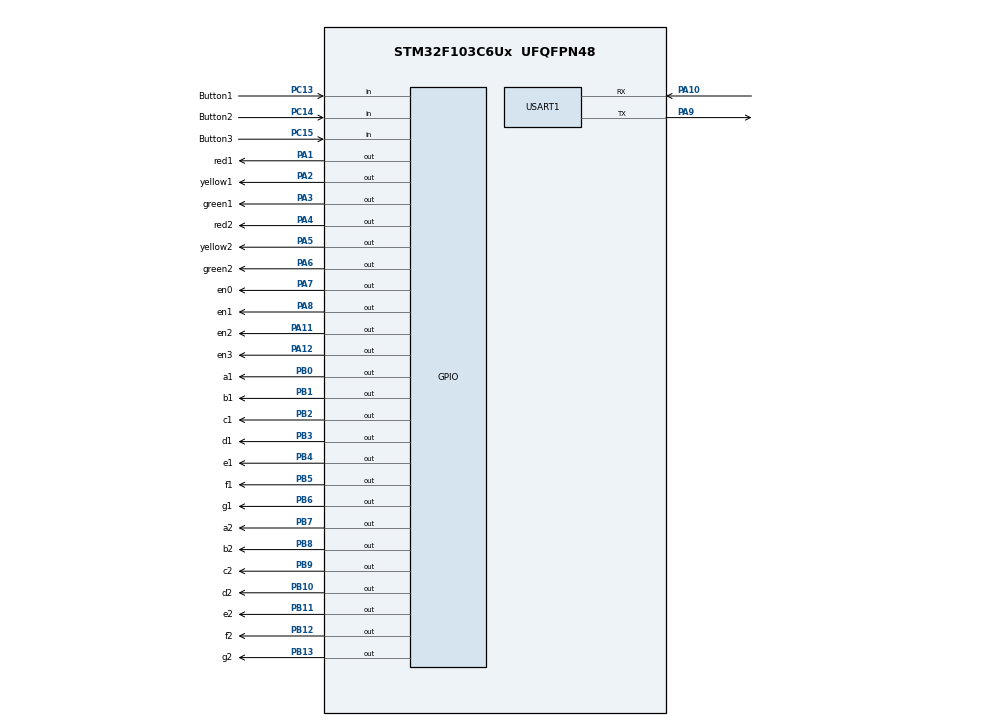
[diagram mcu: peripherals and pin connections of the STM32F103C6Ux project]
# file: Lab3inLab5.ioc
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Mcu.Family=STM32F1
Mcu.Name=STM32F103C6Ux
Mcu.Package=UFQFPN48
NVIC.PriorityGroup=NVIC_PRIORITYGROUP_4
NVIC.TIM2_IRQn=true\:0\:0\:false\:false\:true\:true\:true
NVIC.USART1_IRQn=true\:0\:0\:false\:false\:true\:true\:true
PA1.GPIO_Label=red1
PA1.Signal=GPIO_Output
PA10.Mode=Asynchronous
PA10.Signal=USART1_RX
PA11.GPIO_Label=en2
PA11.Signal=GPIO_Output
PA12.GPIO_Label=en3
PA12.Signal=GPIO_Output
PA2.GPIO_Label=yellow1
PA2.Signal=GPIO_Output
PA3.GPIO_Label=green1
PA3.Signal=GPIO_Output
PA4.GPIO_Label=red2
PA4.Signal=GPIO_Output
PA5.GPIO_Label=yellow2
PA5.Signal=GPIO_Output
PA6.GPIO_Label=green2
PA6.Signal=GPIO_Output
PA7.GPIO_Label=en0
PA7.Signal=GPIO_Output
PA8.GPIO_Label=en1
PA8.Signal=GPIO_Output
PA9.Mode=Asynchronous
PA9.Signal=USART1_TX
PB0.GPIO_Label=a1
PB0.Signal=GPIO_Output
PB1.GPIO_Label=b1
PB1.Signal=GPIO_Output
PB10.GPIO_Label=d2
PB10.Signal=GPIO_Output
PB11.GPIO_Label=e2
PB11.Signal=GPIO_Output
PB12.GPIO_Label=f2
PB12.Signal=GPIO_Output
PB13.GPIO_Label=g2
PB13.Signal=GPIO_Output
PB2.GPIO_Label=c1
PB2.Signal=GPIO_Output
PB3.GPIO_Label=d1
PB3.Signal=GPIO_Output
PB4.GPIO_Label=e1
PB4.Signal=GPIO_Output
PB5.GPIO_Label=f1
PB5.Signal=GPIO_Output
PB6.GPIO_Label=g1
PB6.Signal=GPIO_Output
PB7.GPIO_Label=a2
PB7.Signal=GPIO_Output
PB8.GPIO_Label=b2
PB8.Signal=GPIO_Output
PB9.GPIO_Label=c2
PB9.Signal=GPIO_Output
PC13-TAMPER-RTC.GPIO_Label=Button1
PC13-TAMPER-RTC.GPIO_PuPd=GPIO_PULLUP
PC13-TAMPER-RTC.Signal=GPIO_Input
PC14-OSC32_IN.GPIO_Label=Button2
PC14-OSC32_IN.GPIO_PuPd=GPIO_PULLUP
PC14-OSC32_IN.Signal=GPIO_Input
PC15-OSC32_OUT.GPIO_Label=Button3
PC15-OSC32_OUT.GPIO_PuPd=GPIO_PULLUP
PC15-OSC32_OUT.Signal=GPIO_Input
ProjectManager.HeapSize=0x200
ProjectManager.StackSize=0x400
ProjectManager.TargetToolchain=STM32CubeIDE
RCC.APB1Freq_Value=8000000
RCC.APB2Freq_Value=8000000
TIM2.Period=10
TIM2.Prescaler=7999
USART1.VirtualMode=VM_ASYNC
VP_SYS_VS_ND.Mode=No_Debug
VP_TIM2_VS_ClockSourceINT.Mode=Internal
board=custom

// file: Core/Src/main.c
/* USER CODE BEGIN Header */
/**
  ******************************************************************************
  * @file           : main.c
  * @brief          : Main program body
  ******************************************************************************
  * @attention
  *
  * <h2><center>&copy; Copyright (c) 2023 STMicroelectronics.
  * All rights reserved.</center></h2>
  *
  * This software component is licensed by ST under BSD 3-Clause license,
  * the "License"; You may not use this file except in compliance with the
  * License. You may obtain a copy of the License at:
  *                        opensource.org/licenses/BSD-3-Clause
  *
  ******************************************************************************
  */
/* USER CODE END Header */
#include "main.h"

/* USER CODE BEGIN Includes */
#include "global.h"
/* USER CODE END Includes */

TIM_HandleTypeDef htim2;

UART_HandleTypeDef huart1;

void SystemClock_Config(void);
static void MX_GPIO_Init(void);
static void MX_TIM2_Init(void);
static void MX_USART1_UART_Init(void);

void sendSignal(char *str){
	HAL_UART_Transmit(&huart1,(void *) str, strlen(str), 10);
}
int main(void)
{

  /* MCU Configuration--------------------------------------------------------*/

  /* Reset of all peripherals, Initializes the Flash interface and the Systick. */
  HAL_Init();

  /* Configure the system clock */
  SystemClock_Config();

  /* Initialize all configured peripherals */
  MX_GPIO_Init();
  MX_TIM2_Init();
  MX_USART1_UART_Init();
  /* USER CODE BEGIN 2 */
HAL_TIM_Base_Start_IT(&htim2);
  /* USER CODE END 2 */

  /* Infinite loop */
  /* USER CODE BEGIN WHILE */
	SCH_Add_Task(fsm_auto, 0, 100);
	SCH_Add_Task(fsm_manual, 1, 10);
	SCH_Add_Task(scanLed, 2, 25);
//	SCH_Add_Task(getKeyinput, 4, 1);

  while (1)
  {
    /* USER CODE END WHILE */
	  SCH_Dispatch_Tasks();
  }
}

void SystemClock_Config(void)
{
  RCC_OscInitTypeDef RCC_OscInitStruct = {0};
  RCC_ClkInitTypeDef RCC_ClkInitStruct = {0};

  /** Initializes the RCC Oscillators according to the specified parameters
  * in the RCC_OscInitTypeDef structure.
  */
  RCC_OscInitStruct.OscillatorType = RCC_OSCILLATORTYPE_HSI;
  RCC_OscInitStruct.HSIState = RCC_HSI_ON;
  RCC_OscInitStruct.HSICalibrationValue = RCC_HSICALIBRATION_DEFAULT;
  RCC_OscInitStruct.PLL.PLLState = RCC_PLL_NONE;
  if (HAL_RCC_OscConfig(&RCC_OscInitStruct) != HAL_OK)
  {
    Error_Handler();
  }
  /** Initializes the CPU, AHB and APB buses clocks
  */
  RCC_ClkInitStruct.ClockType = RCC_CLOCKTYPE_HCLK|RCC_CLOCKTYPE_SYSCLK
                              |RCC_CLOCKTYPE_PCLK1|RCC_CLOCKTYPE_PCLK2;
  RCC_ClkInitStruct.SYSCLKSource = RCC_SYSCLKSOURCE_HSI;
  RCC_ClkInitStruct.AHBCLKDivider = RCC_SYSCLK_DIV1;
  RCC_ClkInitStruct.APB1CLKDivider = RCC_HCLK_DIV1;
  RCC_ClkInitStruct.APB2CLKDivider = RCC_HCLK_DIV1;

  if (HAL_RCC_ClockConfig(&RCC_ClkInitStruct, FLASH_LATENCY_0) != HAL_OK)
  {
    Error_Handler();
  }
}

static void MX_TIM2_Init(void)
{

  TIM_ClockConfigTypeDef sClockSourceConfig = {0};
  TIM_MasterConfigTypeDef sMasterConfig = {0};

  htim2.Instance = TIM2;
  htim2.Init.Prescaler = 7999;
  htim2.Init.CounterMode = TIM_COUNTERMODE_UP;
  htim2.Init.Period = 10;
  htim2.Init.ClockDivision = TIM_CLOCKDIVISION_DIV1;
  htim2.Init.AutoReloadPreload = TIM_AUTORELOAD_PRELOAD_DISABLE;
  if (HAL_TIM_Base_Init(&htim2) != HAL_OK)
  {
    Error_Handler();
  }
  sClockSourceConfig.ClockSource = TIM_CLOCKSOURCE_INTERNAL;
  if (HAL_TIM_ConfigClockSource(&htim2, &sClockSourceConfig) != HAL_OK)
  {
    Error_Handler();
  }
  sMasterConfig.MasterOutputTrigger = TIM_TRGO_RESET;
  sMasterConfig.MasterSlaveMode = TIM_MASTERSLAVEMODE_DISABLE;
  if (HAL_TIMEx_MasterConfigSynchronization(&htim2, &sMasterConfig) != HAL_OK)
  {
    Error_Handler();
  }

}

static void MX_USART1_UART_Init(void)
{

  huart1.Instance = USART1;
  huart1.Init.BaudRate = 115200;
  huart1.Init.WordLength = UART_WORDLENGTH_8B;
  huart1.Init.StopBits = UART_STOPBITS_1;
  huart1.Init.Parity = UART_PARITY_NONE;
  huart1.Init.Mode = UART_MODE_TX_RX;
  huart1.Init.HwFlowCtl = UART_HWCONTROL_NONE;
  huart1.Init.OverSampling = UART_OVERSAMPLING_16;
  if (HAL_UART_Init(&huart1) != HAL_OK)
  {
    Error_Handler();
  }

}

static void MX_GPIO_Init(void)
{
  GPIO_InitTypeDef GPIO_InitStruct = {0};

  /* GPIO Ports Clock Enable */
  __HAL_RCC_GPIOC_CLK_ENABLE();
  __HAL_RCC_GPIOA_CLK_ENABLE();
  __HAL_RCC_GPIOB_CLK_ENABLE();

  /*Configure GPIO pin Output Level */
  HAL_GPIO_WritePin(GPIOA, red1_Pin|yellow1_Pin|green1_Pin|red2_Pin
                          |yellow2_Pin|green2_Pin|en0_Pin|en1_Pin
                          |en2_Pin|en3_Pin, GPIO_PIN_RESET);

  /*Configure GPIO pin Output Level */
  HAL_GPIO_WritePin(GPIOB, a1_Pin|b1_Pin|c1_Pin|d2_Pin
                          |e2_Pin|f2_Pin|g2_Pin|d1_Pin
                          |e1_Pin|f1_Pin|g1_Pin|a2_Pin
                          |b2_Pin|c2_Pin, GPIO_PIN_RESET);

  /*Configure GPIO pins : Button1_Pin Button2_Pin Button3_Pin */
  GPIO_InitStruct.Pin = Button1_Pin|Button2_Pin|Button3_Pin;
  GPIO_InitStruct.Mode = GPIO_MODE_INPUT;
  GPIO_InitStruct.Pull = GPIO_PULLUP;
  HAL_GPIO_Init(GPIOC, &GPIO_InitStruct);

  /*Configure GPIO pins : red1_Pin yellow1_Pin green1_Pin red2_Pin
                           yellow2_Pin green2_Pin en0_Pin en1_Pin
                           en2_Pin en3_Pin */
  GPIO_InitStruct.Pin = red1_Pin|yellow1_Pin|green1_Pin|red2_Pin
                          |yellow2_Pin|green2_Pin|en0_Pin|en1_Pin
                          |en2_Pin|en3_Pin;
  GPIO_InitStruct.Mode = GPIO_MODE_OUTPUT_PP;
  GPIO_InitStruct.Pull = GPIO_NOPULL;
  GPIO_InitStruct.Speed = GPIO_SPEED_FREQ_LOW;
  HAL_GPIO_Init(GPIOA, &GPIO_InitStruct);

  /*Configure GPIO pins : a1_Pin b1_Pin c1_Pin d2_Pin
                           e2_Pin f2_Pin g2_Pin d1_Pin
                           e1_Pin f1_Pin g1_Pin a2_Pin
                           b2_Pin c2_Pin */
  GPIO_InitStruct.Pin = a1_Pin|b1_Pin|c1_Pin|d2_Pin
                          |e2_Pin|f2_Pin|g2_Pin|d1_Pin
                          |e1_Pin|f1_Pin|g1_Pin|a2_Pin
                          |b2_Pin|c2_Pin;
  GPIO_InitStruct.Mode = GPIO_MODE_OUTPUT_PP;
  GPIO_InitStruct.Pull = GPIO_NOPULL;
  GPIO_InitStruct.Speed = GPIO_SPEED_FREQ_LOW;
  HAL_GPIO_Init(GPIOB, &GPIO_InitStruct);

}

/* USER CODE BEGIN 4 */
void HAL_TIM_PeriodElapsedCallback(TIM_HandleTypeDef *htim){
	SCH_Update();
//	timerRun();
	getKeyinput();
}
/* USER CODE END 4 */

void Error_Handler(void)
{
  __disable_irq();
  while (1)
  {
  }
}

/************************ (C) COPYRIGHT STMicroelectronics *****END OF FILE****/
